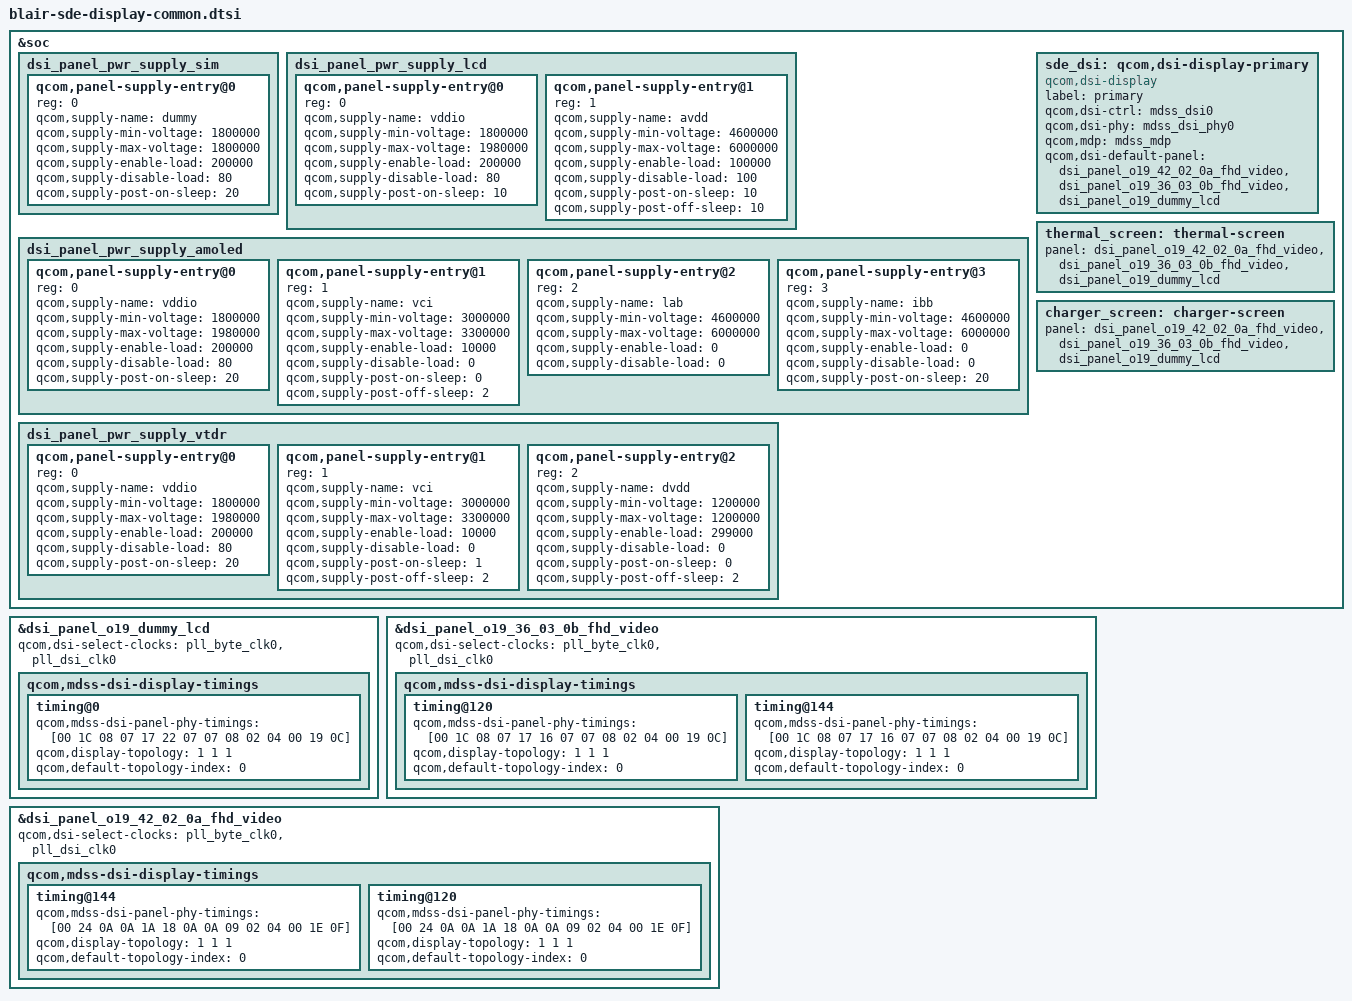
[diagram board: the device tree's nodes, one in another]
#include "blair-sde-display-pinctrl.dtsi"
#include "dsi_panel_o19_36_03_0b_fhd_video.dtsi"
#include "dsi_panel_o19_42_02_0a_fhd_video.dtsi"
#include "dsi_panel_o19_dummy_lcd.dtsi"
&soc {
	dsi_panel_pwr_supply_sim: dsi_panel_pwr_supply_sim {
		#address-cells = <1>;
		#size-cells = <0>;

		qcom,panel-supply-entry@0 {
			reg = <0>;
			qcom,supply-name = "dummy";
			qcom,supply-min-voltage = <1800000>;
			qcom,supply-max-voltage = <1800000>;
			qcom,supply-enable-load = <200000>;
			qcom,supply-disable-load = <80>;
			qcom,supply-post-on-sleep = <20>;
		};
	};

	dsi_panel_pwr_supply_lcd: dsi_panel_pwr_supply_lcd {
		#address-cells = <1>;
		#size-cells = <0>;

		qcom,panel-supply-entry@0 {
			reg = <0>;
			qcom,supply-name = "vddio";
			qcom,supply-min-voltage = <1800000>;
			qcom,supply-max-voltage = <1980000>;
			qcom,supply-enable-load = <200000>;
			qcom,supply-disable-load = <80>;
			qcom,supply-post-on-sleep = <10>;
		};

		qcom,panel-supply-entry@1 {
			reg = <1>;
			qcom,supply-name = "avdd";
			qcom,supply-min-voltage = <4600000>;
			qcom,supply-max-voltage = <6000000>;
			qcom,supply-enable-load = <100000>;
			qcom,supply-disable-load = <100>;
			qcom,supply-post-on-sleep = <10>;
			qcom,supply-post-off-sleep = <10>;
		};
	};

	dsi_panel_pwr_supply_amoled: dsi_panel_pwr_supply_amoled {
		#address-cells = <1>;
		#size-cells = <0>;

		qcom,panel-supply-entry@0 {
			reg = <0>;
			qcom,supply-name = "vddio";
			qcom,supply-min-voltage = <1800000>;
			qcom,supply-max-voltage = <1980000>;
			qcom,supply-enable-load = <200000>;
			qcom,supply-disable-load = <80>;
			qcom,supply-post-on-sleep = <20>;
		};

		qcom,panel-supply-entry@1 {
			reg = <1>;
			qcom,supply-name = "vci";
			qcom,supply-min-voltage = <3000000>;
			qcom,supply-max-voltage = <3300000>;
			qcom,supply-enable-load = <10000>;
			qcom,supply-disable-load = <0>;
			qcom,supply-post-on-sleep = <0>;
			qcom,supply-post-off-sleep = <2>;
		};

		 qcom,panel-supply-entry@2 {
			reg = <2>;
			qcom,supply-name = "lab";
			qcom,supply-min-voltage = <4600000>;
			qcom,supply-max-voltage = <6000000>;
			qcom,supply-enable-load = <0>;
			qcom,supply-disable-load = <0>;
		};

		qcom,panel-supply-entry@3 {
			reg = <3>;
			qcom,supply-name = "ibb";
			qcom,supply-min-voltage = <4600000>;
			qcom,supply-max-voltage = <6000000>;
			qcom,supply-enable-load = <0>;
			qcom,supply-disable-load = <0>;
			qcom,supply-post-on-sleep = <20>;
		};
	};

	dsi_panel_pwr_supply_vtdr: dsi_panel_pwr_supply_vtdr {
		#address-cells = <1>;
		#size-cells = <0>;

		qcom,panel-supply-entry@0 {
			reg = <0>;
			qcom,supply-name = "vddio";
			qcom,supply-min-voltage = <1800000>;
			qcom,supply-max-voltage = <1980000>;
			qcom,supply-enable-load = <200000>;
			qcom,supply-disable-load = <80>;
			qcom,supply-post-on-sleep = <20>;
		};

		qcom,panel-supply-entry@1 {
			reg = <1>;
			qcom,supply-name = "vci";
			qcom,supply-min-voltage = <3000000>;
			qcom,supply-max-voltage = <3300000>;
			qcom,supply-enable-load = <10000>;
			qcom,supply-disable-load = <0>;
			qcom,supply-post-on-sleep = <1>;
			qcom,supply-post-off-sleep = <2>;
		};

		 qcom,panel-supply-entry@2 {
			reg = <2>;
			qcom,supply-name = "dvdd";
			qcom,supply-min-voltage = <1200000>;
			qcom,supply-max-voltage = <1200000>;
			qcom,supply-enable-load = <299000>;
			qcom,supply-disable-load = <0>;
			qcom,supply-post-on-sleep = <0>;
			qcom,supply-post-off-sleep = <2>;
		};
	};

	sde_dsi: qcom,dsi-display-primary {
		compatible = "qcom,dsi-display";
		label = "primary";

		qcom,dsi-ctrl = <&mdss_dsi0>;
		qcom,dsi-phy = <&mdss_dsi_phy0>;

		//pinctrl-names = "panel_active", "panel_suspend";
		//pinctrl-0 = <&sde_dsi_default &sde_te_active>;
		//pinctrl-1 = <&sde_te_suspend>;

		//qcom,platform-te-gpio = <&tlmm 23 0>;
		//qcom,panel-te-source = <0>;

		qcom,mdp = <&mdss_mdp>;
                qcom,dsi-default-panel = <&dsi_panel_o19_42_02_0a_fhd_video &dsi_panel_o19_36_03_0b_fhd_video &dsi_panel_o19_dummy_lcd>;
	};

	thermal_screen: thermal-screen {
		panel = <&dsi_panel_o19_42_02_0a_fhd_video &dsi_panel_o19_36_03_0b_fhd_video &dsi_panel_o19_dummy_lcd>;
        };

	charger_screen: charger-screen {
		panel = <&dsi_panel_o19_42_02_0a_fhd_video &dsi_panel_o19_36_03_0b_fhd_video &dsi_panel_o19_dummy_lcd>;
	};
};

&dsi_panel_o19_dummy_lcd {
	qcom,dsi-select-clocks = "pll_byte_clk0", "pll_dsi_clk0";
	qcom,mdss-dsi-display-timings {
		timing@0 {
			qcom,mdss-dsi-panel-phy-timings = [00 1C 08 07 17 22 07
				07 08 02 04 00 19 0C];
			qcom,display-topology = <1 1 1>;
			qcom,default-topology-index = <0>;
		};
	};
};

&dsi_panel_o19_36_03_0b_fhd_video {
	qcom,dsi-select-clocks = "pll_byte_clk0", "pll_dsi_clk0";
	qcom,mdss-dsi-display-timings {
		timing@120 {
			qcom,mdss-dsi-panel-phy-timings = [00 1C 08 07 17 16 07
				07 08 02 04 00 19 0C];
			qcom,display-topology = <1 1 1>;
			qcom,default-topology-index = <0>;
		};
		timing@144 {
			qcom,mdss-dsi-panel-phy-timings = [00 1C 08 07 17 16 07
				07 08 02 04 00 19 0C];
			qcom,display-topology = <1 1 1>;
			qcom,default-topology-index = <0>;
		};
	};
};

&dsi_panel_o19_42_02_0a_fhd_video {
	qcom,dsi-select-clocks = "pll_byte_clk0", "pll_dsi_clk0";
	qcom,mdss-dsi-display-timings {
		timing@144 {
			qcom,mdss-dsi-panel-phy-timings = [00 24 0A 0A 1A 18 0A
				0A 09 02 04 00 1E 0F];
			qcom,display-topology = <1 1 1>;
			qcom,default-topology-index = <0>;
		};
		timing@120 {
			qcom,mdss-dsi-panel-phy-timings = [00 24 0A 0A 1A 18 0A
				0A 09 02 04 00 1E 0F];
			qcom,display-topology = <1 1 1>;
			qcom,default-topology-index = <0>;
		};
	};
};
